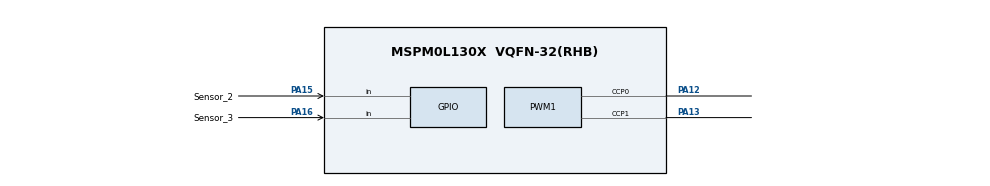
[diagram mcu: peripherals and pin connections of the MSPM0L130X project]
/**
 * @cliArgs --device "MSPM0L130X" --package "VQFN-32(RHB)" --part "Default" --product "mspm0_sdk@2.01.00.03"
 * @versions {"tool":"1.20.0+3587"}
 */

/**
 * Import the modules used in this configuration.
 */
const GPIO   = scripting.addModule("/ti/driverlib/GPIO", {}, false);
const GPIO1  = GPIO.addInstance();
const GPIO2  = GPIO.addInstance();
const GPIO3  = GPIO.addInstance();
const GPIO4  = GPIO.addInstance();
const GPIO5  = GPIO.addInstance();
const GPIO6  = GPIO.addInstance();
const PWM    = scripting.addModule("/ti/driverlib/PWM", {}, false);
const PWM1   = PWM.addInstance();
const SYSCTL = scripting.addModule("/ti/driverlib/SYSCTL");

/**
 * Write custom configuration values to the imported modules.
 */
GPIO1.$name                         = "TB6612_1_A";
GPIO1.port                          = "PORTA";
GPIO1.associatedPins.create(2);
GPIO1.associatedPins[0].assignedPin = "4";
GPIO1.associatedPins[0].$name       = "AIN_1_1";
GPIO1.associatedPins[1].assignedPin = "5";
GPIO1.associatedPins[1].$name       = "AIN_1_2";

const Board = scripting.addModule("/ti/driverlib/Board", {}, false);

GPIO2.$name                         = "TB6612_1_B";
GPIO2.port                          = "PORTA";
GPIO2.associatedPins.create(2);
GPIO2.associatedPins[0].assignedPin = "6";
GPIO2.associatedPins[0].$name       = "BIN_1_1";
GPIO2.associatedPins[1].assignedPin = "7";
GPIO2.associatedPins[1].$name       = "BIN_1_2";

GPIO3.$name                              = "TCRT5000";
GPIO3.port                               = "PORTA";
GPIO3.associatedPins.create(5);
GPIO3.associatedPins[0].$name            = "Sensor_1";
GPIO3.associatedPins[0].direction        = "INPUT";
GPIO3.associatedPins[0].internalResistor = "PULL_UP";
GPIO3.associatedPins[0].assignedPin      = "24";
GPIO3.associatedPins[1].$name            = "Sensor_2";
GPIO3.associatedPins[1].direction        = "INPUT";
GPIO3.associatedPins[1].assignedPin      = "15";
GPIO3.associatedPins[1].internalResistor = "PULL_UP";
GPIO3.associatedPins[1].pin.$assign      = "PA15";
GPIO3.associatedPins[2].$name            = "Sensor_3";
GPIO3.associatedPins[2].direction        = "INPUT";
GPIO3.associatedPins[2].assignedPin      = "16";
GPIO3.associatedPins[2].internalResistor = "PULL_UP";
GPIO3.associatedPins[2].pin.$assign      = "PA16";
GPIO3.associatedPins[3].$name            = "Sensor_4";
GPIO3.associatedPins[3].direction        = "INPUT";
GPIO3.associatedPins[3].assignedPin      = "17";
GPIO3.associatedPins[3].internalResistor = "PULL_UP";
GPIO3.associatedPins[4].$name            = "Sensor_5";
GPIO3.associatedPins[4].direction        = "INPUT";
GPIO3.associatedPins[4].assignedPin      = "18";
GPIO3.associatedPins[4].internalResistor = "PULL_UP";

GPIO4.$name                              = "Get_CircleNum";
GPIO4.port                               = "PORTA";
GPIO4.associatedPins.create(5);
GPIO4.associatedPins[0].$name            = "Num_1";
GPIO4.associatedPins[0].direction        = "INPUT";
GPIO4.associatedPins[0].internalResistor = "PULL_UP";
GPIO4.associatedPins[0].assignedPin      = "26";
GPIO4.associatedPins[1].$name            = "Num_2";
GPIO4.associatedPins[1].direction        = "INPUT";
GPIO4.associatedPins[1].assignedPin      = "27";
GPIO4.associatedPins[1].internalResistor = "PULL_UP";
GPIO4.associatedPins[2].$name            = "Num_3";
GPIO4.associatedPins[2].direction        = "INPUT";
GPIO4.associatedPins[2].internalResistor = "PULL_UP";
GPIO4.associatedPins[2].assignedPin      = "21";
GPIO4.associatedPins[3].$name            = "Num_4";
GPIO4.associatedPins[3].direction        = "INPUT";
GPIO4.associatedPins[3].internalResistor = "PULL_UP";
GPIO4.associatedPins[3].assignedPin      = "22";
GPIO4.associatedPins[4].$name            = "Num_5";
GPIO4.associatedPins[4].direction        = "INPUT";
GPIO4.associatedPins[4].internalResistor = "PULL_UP";
GPIO4.associatedPins[4].assignedPin      = "3";

GPIO5.$name                         = "BUZZER";
GPIO5.associatedPins[0].$name       = "BUZZER_1";
GPIO5.associatedPins[0].assignedPin = "0";

GPIO6.$name                              = "Startup";
GPIO6.port                               = "PORTA";
GPIO6.associatedPins[0].direction        = "INPUT";
GPIO6.associatedPins[0].$name            = "StartKey";
GPIO6.associatedPins[0].ioStructure      = "SD";
GPIO6.associatedPins[0].internalResistor = "PULL_UP";
GPIO6.associatedPins[0].assignedPin      = "14";

PWM1.$name                      = "PWM_0";
PWM1.timerCount                 = 16000;
PWM1.pwmMode                    = "EDGE_ALIGN_UP";
PWM1.peripheral.$assign         = "TIMG0";
PWM1.peripheral.ccp0Pin.$assign = "PA12";
PWM1.peripheral.ccp1Pin.$assign = "PA13";
PWM1.PWM_CHANNEL_0.$name        = "ti_driverlib_pwm_PWMTimerCC0";
PWM1.PWM_CHANNEL_1.$name        = "ti_driverlib_pwm_PWMTimerCC2";
PWM1.ccp0PinConfig.$name        = "ti_driverlib_gpio_GPIOPinGeneric0";
PWM1.ccp1PinConfig.$name        = "ti_driverlib_gpio_GPIOPinGeneric2";


/**
 * Pinmux solution for unlocked pins/peripherals. This ensures that minor changes to the automatic solver in a future
 * version of the tool will not impact the pinmux you originally saw.  These lines can be completely deleted in order to
 * re-solve from scratch.
 */
GPIO1.associatedPins[0].pin.$suggestSolution = "PA4";
GPIO1.associatedPins[1].pin.$suggestSolution = "PA5";
Board.peripheral.$suggestSolution            = "DEBUGSS";
Board.peripheral.swclkPin.$suggestSolution   = "PA20";
Board.peripheral.swdioPin.$suggestSolution   = "PA19";
GPIO2.associatedPins[0].pin.$suggestSolution = "PA6";
GPIO2.associatedPins[1].pin.$suggestSolution = "PA7";
GPIO3.associatedPins[0].pin.$suggestSolution = "PA24/OPA0.IN0-";
GPIO3.associatedPins[3].pin.$suggestSolution = "PA17/OPA1.IN0-";
GPIO3.associatedPins[4].pin.$suggestSolution = "PA18";
GPIO4.associatedPins[0].pin.$suggestSolution = "PA26";
GPIO4.associatedPins[1].pin.$suggestSolution = "PA27";
GPIO4.associatedPins[2].pin.$suggestSolution = "PA21";
GPIO4.associatedPins[3].pin.$suggestSolution = "PA22";
GPIO4.associatedPins[4].pin.$suggestSolution = "PA3";
GPIO5.associatedPins[0].pin.$suggestSolution = "PA0";
GPIO6.associatedPins[0].pin.$suggestSolution = "PA14";
SYSCTL.peripheral.$suggestSolution           = "SYSCTL";
